# Ij7am_cnm_wave521cl_main_0_pri_m_vbusm_r_bw_limiter0_REGS register map
Vendor: Texas Instruments
Peripheral module from a debugger description file (folder J7_AHP).
Registers are 32-bit, read-only, reset 0x0 unless marked. A register's access mark holds for its fields unless they carry their own. Offsets are as the file gives them; lines under a group give offsets from that group; [hi:lo] are bit positions; {n}, {i} and the like mark numbered series; 'fields as' and 'values as' point back to an identical list; <NAME> marks a mode.

## Ij7am_cnm_wave521cl_main_0_pri_m_vbusm_r_bw_limiter0_REGS
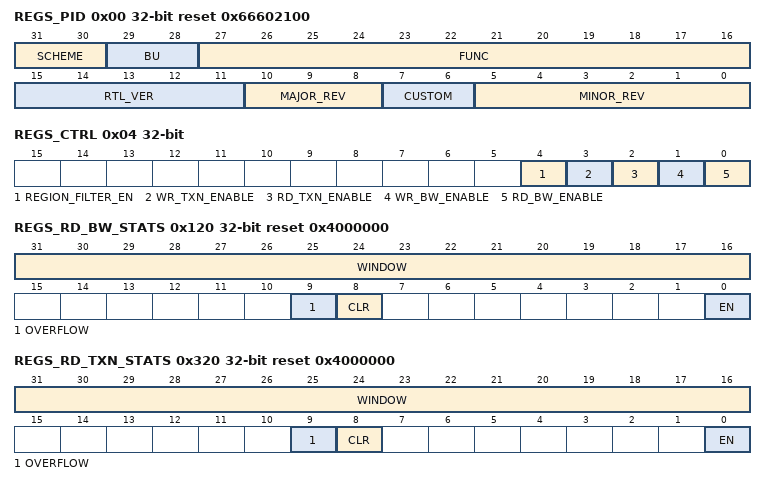
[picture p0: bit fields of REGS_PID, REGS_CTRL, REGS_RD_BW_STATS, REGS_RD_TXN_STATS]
0x00 REGS_PID reset 0x66602100
  [31:30] SCHEME — PID scheme
  [29:28] BU — PID bu identifier
  [27:16] FUNC — PID function identifier
  [15:11] RTL_VER — PID RTL version number
  [10:8] MAJOR_REV — PID Major revision number
  [7:6] CUSTOM — PID custom
  [5:0] MINOR_REV — PID Minor revision number
0x04 REGS_CTRL rw
  [4] REGION_FILTER_EN — Enable the region filter, which will only apply the bandwith and transaction limits to the configured address regions
  [3] WR_TXN_ENABLE — Enable limiting maximum outstanding write transactions
  [2] RD_TXN_ENABLE — Enable limiting maximum outstanding read transactions
  [1] WR_BW_ENABLE — Enable write bandwidth limiting
  [0] RD_BW_ENABLE — Enable read bandwidth limiting
0x100 REGS_RD_BW_CIR rw
  [31:0] CIR — Committed Information Rate
0x104 REGS_RD_BW_PIR rw
  [31:0] PIR — Peak Information Rate
0x108 REGS_RD_BW_BURST_OFFSET rw
  [15:0] OFFSET — Burst Offset - the number of bytes before the Committed Information Rate is applied at startup or after a period of inactivity. Peak Information Rate will still apply
0x10C REGS_RD_BW_INFO
  [1:0] COLOR — Read Bandwidth three-color marker output from rategen submodule
0x120 REGS_RD_BW_STATS access per field reset 0x4000000
  [31:16] WINDOW rw — Statistics window size. This cannot be set to 0. If 16'd0 is written, it will be set to the reset value of 16'd1024
  [9] OVERFLOW ro — Statistics overflow error
  [8] CLR wo — Clear statistics data. Resets statistics counters at 0
  [0] EN rw — Enable read bandwidth statistics
0x124 REGS_RD_BW_STATS_THRSHLD rw
  [31:0] THRESHOLD — Read bandwidth stats threshold in bytes. Note that this is total bytes, unlike CIR and PIR. CIR and PIR are based on a rolling window, and the statistics threshold is based on a fixed window. This will still take into account DDR bytes used, so can be compared to CIR and PIR directly if the bandwidths are converted via the equations for CIR and PIR. The threshold bandwidth is programmed here as bytes per window
0x128 REGS_RD_BW_WINDOWS_CNT
  [31:0] VAL — Read bandwidth window count - the number of windows elapsed since statistics collection began
0x12C REGS_RD_BW_CIR_CNT
  [31:0] VAL — The total number of statistics windows in which Read Commit Information Rate occurred. Note that if PIR is set to a lower value than CIR or if the burst offset feature is used, this will also count times that PIR is reached.
0x130 REGS_RD_BW_PIR_CNT
  [31:0] VAL — The total number of statistics windows in which Read Peak Information Rate occurred
0x134 REGS_RD_BW_THRSHLD_CNT
  [31:0] VAL — The total number of statistics windows in which Read bytes transferred exceeded the statistics threshold
0x138 REGS_RD_BYTES_MAX
  [31:0] VAL — Max number of bytes in a single window. This number accounts for DDR bandwidth consumed, not simply the accumulation of the packet bytecnt values across a window. The max bandwidth calculation is the total bytes value in this MMR divided by the windows size in RD_BW_STATS.window and multiplied with the interface frequency: RD_BYTES_MAX * FREQ / RD_BW_STATS.window
0x300 REGS_RD_TXN rw reset 0x40
  [15:0] LIMIT — The maximum number of outstanding read transactions allowed. NOTE: This cannot be programmed to a zero. If a zero is written, it will default to the reset value of 16'd64, as a limit of zero outstanding transactions would hang the interface.
0x30C REGS_RD_TXN_INFO
  [6:0] OCC — Read transaction scoreboard occupancy
0x320 REGS_RD_TXN_STATS access per field reset 0x4000000
  [31:16] WINDOW rw — Statistics window size. This cannot be set to 0. If 16'd0 is written, it will be set to the reset value of 16'd1024
  [9] OVERFLOW ro — Statistics overflow error
  [8] CLR wo — Clear statistics data. Resets statistics counters at 0
  [0] EN rw — Enable read transaction statistics
0x324 REGS_RD_TXN_STATS_THRSHLD rw
  [15:0] THRESHOLD — Read transaction statistics threshold. The threshold can be set to any value, though it will saturate at the outstanding transaction limit if it is set to a value greater than the programmed outstanding read transaction limit
0x328 REGS_RD_TXN_WINDOWS_CNT
  [31:0] VAL — Read transaction window count - the number of windows elapsed since statistics collection began
0x32C REGS_RD_TXN_LMT_CNT
  [31:0] VAL — The number of statistics windows in which the outstanding read transaction limit was reached
0x330 REGS_RD_TXN_THRSHLD_CNT
  [31:0] VAL — The number of statistics windows in which the number of outstanding read transactions was greater than or equal to the threshold in RD_TXN_STATS_THRSHLD
0x334 REGS_RD_TXN_LIMIT_TOTAL
  [31:0] VAL — The total number of cycles with the read transactions outstanding at the programmed limit since statistics collection began
0x338 REGS_RD_TXN_THRSHLD_TOTAL
  [31:0] VAL — The total number of cycles with read transactions outstanding greater than or equal to the statistics threshold in RD_TXN_STATS_THRSHLD since statistics collection began
0x33C REGS_RD_TXN_MAX
  [15:0] VAL — The maximum outstanding read transactions at any point in time, regardless of the programmed limit
